VERSION "ACC_ADAS_TC014 1.0"

NS_ :

BS_:

BU_: ACC

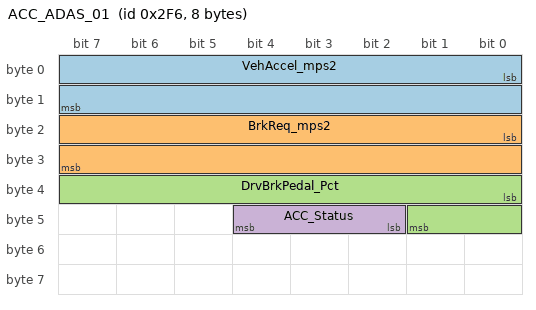
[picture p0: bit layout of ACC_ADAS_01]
BO_ 758 ACC_ADAS_01: 8 ACC
 SG_ VehAccel_mps2 : 0|16@1- (0.001,0) [-32.768|32.767] "m/s^2" Vector__XXX
 SG_ BrkReq_mps2 : 16|16@1- (0.001,0) [-32.768|32.767] "m/s^2" Vector__XXX
 SG_ DrvBrkPedal_Pct : 32|10@1+ (0.1,0) [0|102.3] "%" Vector__XXX
 SG_ ACC_Status : 42|3@1+ (1,0) [0|7] "1" Vector__XXX
